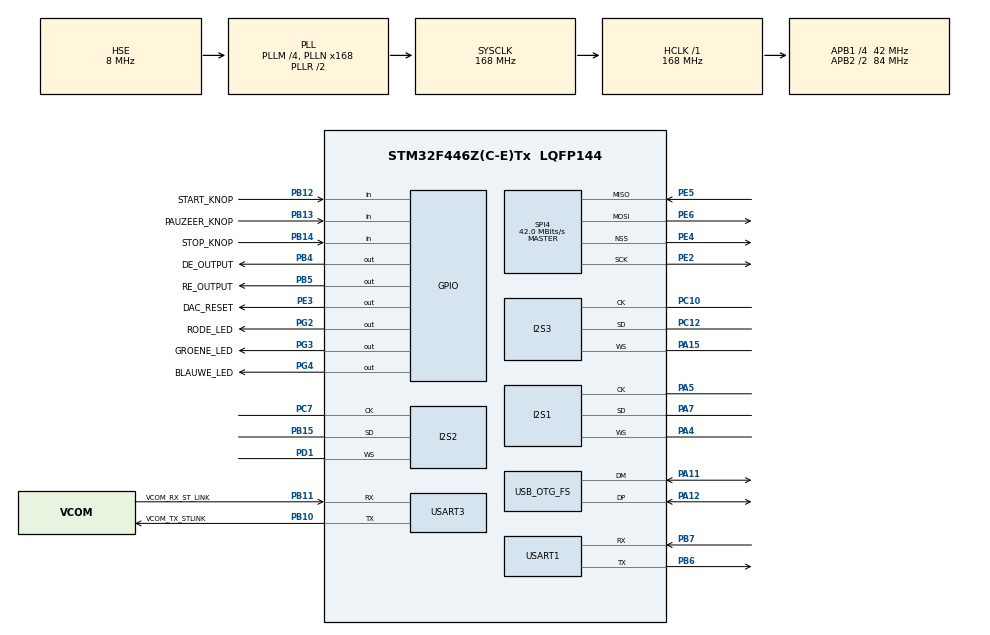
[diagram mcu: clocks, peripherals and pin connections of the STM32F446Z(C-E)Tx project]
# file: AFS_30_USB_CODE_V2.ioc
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I2S1.AudioFreq=I2S_AUDIOFREQ_48K
I2S1.DataFormat=I2S_DATAFORMAT_24B
I2S1.ErrorAudioFreq=1.72 %
I2S1.FullDuplexMode=I2S_FULLDUPLEXMODE_DISABLE
I2S1.Instance=SPI$Index
I2S1.RealAudioFreq=48.828 KHz
I2S1.Standard=I2S_STANDARD_PHILIPS
I2S1.VirtualMode=I2S_MODE_MASTER
I2S2.AudioFreq=I2S_AUDIOFREQ_48K
I2S2.DataFormat=I2S_DATAFORMAT_24B
I2S2.ErrorAudioFreq=1.72 %
I2S2.FullDuplexMode=I2S_FULLDUPLEXMODE_DISABLE
I2S2.Instance=SPI$Index
I2S2.RealAudioFreq=48.828 KHz
I2S2.VirtualMode=I2S_MODE_MASTER
I2S3.AudioFreq=I2S_AUDIOFREQ_48K
I2S3.DataFormat=I2S_DATAFORMAT_24B
I2S3.ErrorAudioFreq=1.72 %
I2S3.FullDuplexMode=I2S_FULLDUPLEXMODE_DISABLE
I2S3.Instance=SPI$Index
I2S3.RealAudioFreq=48.828 KHz
I2S3.VirtualMode=I2S_MODE_MASTER
Mcu.Family=STM32F4
Mcu.Name=STM32F446Z(C-E)Tx
Mcu.Package=LQFP144
NVIC.OTG_FS_IRQn=true\:0\:0\:false\:false\:true\:false\:true\:true
NVIC.PriorityGroup=NVIC_PRIORITYGROUP_4
PA11.Mode=Device_Only
PA11.Signal=USB_OTG_FS_DM
PA12.Mode=Device_Only
PA12.Signal=USB_OTG_FS_DP
PA13.Mode=Serial_Wire
PA13.Signal=SYS_JTMS-SWDIO
PA14.Mode=Serial_Wire
PA14.Signal=SYS_JTCK-SWCLK
PA15.Mode=Half_Duplex_Master
PA15.Signal=I2S3_WS
PA4.Mode=Half_Duplex_Master
PA4.Signal=I2S1_WS
PA5.Mode=Half_Duplex_Master
PA5.Signal=I2S1_CK
PA7.Mode=Half_Duplex_Master
PA7.Signal=I2S1_SD
PB10.GPIO_Label=VCOM_TX_STLINK
PB10.Mode=Asynchronous
PB10.Signal=USART3_TX
PB11.GPIO_Label=VCOM_RX_ST_LINK
PB11.Mode=Asynchronous
PB11.Signal=USART3_RX
PB12.GPIO_Label=START_KNOP
PB12.Signal=GPIO_Input
PB13.GPIO_Label=PAUZEER_KNOP
PB13.Signal=GPIO_Input
PB14.GPIO_Label=STOP_KNOP
PB14.Signal=GPIO_Input
PB15.Mode=Half_Duplex_Master
PB15.Signal=I2S2_SD
PB4.GPIO_Label=DE_OUTPUT
PB4.Signal=GPIO_Output
PB5.GPIO_Label=RE_OUTPUT
PB5.Signal=GPIO_Output
PB6.Mode=Asynchronous
PB6.Signal=USART1_TX
PB7.Mode=Asynchronous
PB7.Signal=USART1_RX
PC10.Mode=Half_Duplex_Master
PC10.Signal=I2S3_CK
PC12.Mode=Half_Duplex_Master
PC12.Signal=I2S3_SD
PC7.Mode=Half_Duplex_Master
PC7.Signal=I2S2_CK
PD1.Mode=Half_Duplex_Master
PD1.Signal=I2S2_WS
PE2.Mode=Full_Duplex_Master
PE2.Signal=SPI4_SCK
PE3.GPIO_Label=DAC_RESET
PE3.Signal=GPIO_Output
PE4.Mode=NSS_Signal_Hard_Output
PE4.Signal=SPI4_NSS
PE5.Mode=Full_Duplex_Master
PE5.Signal=SPI4_MISO
PE6.Mode=Full_Duplex_Master
PE6.Signal=SPI4_MOSI
PG2.GPIO_Label=RODE_LED
PG2.Signal=GPIO_Output
PG3.GPIO_Label=GROENE_LED
PG3.Signal=GPIO_Output
PG4.GPIO_Label=BLAUWE_LED
PG4.Signal=GPIO_Output
PH0-OSC_IN.Mode=HSE-External-Oscillator
PH0-OSC_IN.Signal=RCC_OSC_IN
PH1-OSC_OUT.Mode=HSE-External-Oscillator
PH1-OSC_OUT.Signal=RCC_OSC_OUT
ProjectManager.HeapSize=0x200
ProjectManager.StackSize=0x400
ProjectManager.TargetToolchain=STM32CubeIDE
RCC.AHBFreq_Value=168000000
RCC.APB1CLKDivider=RCC_HCLK_DIV4
RCC.APB1Freq_Value=42000000
RCC.APB1TimFreq_Value=84000000
RCC.APB2CLKDivider=RCC_HCLK_DIV2
RCC.APB2Freq_Value=84000000
RCC.APB2TimFreq_Value=168000000
RCC.CortexFreq_Value=168000000
RCC.HCLKFreq_Value=168000000
RCC.HSE_VALUE=8000000
RCC.PLLI2SM=6
RCC.PLLI2SN=75
RCC.PLLM=4
RCC.PLLN=168
RCC.PLLQ=7
RCC.SYSCLKFreq_VALUE=168000000
RCC.SYSCLKSource=RCC_SYSCLKSOURCE_PLLRCLK
RCC.USBFreq_Value=48000000
RCC.VCOOutputFreq_Value=336000000
SPI4.BaudRatePrescaler=SPI_BAUDRATEPRESCALER_2
SPI4.CalculateBaudRate=42.0 MBits/s
SPI4.Direction=SPI_DIRECTION_2LINES
SPI4.Mode=SPI_MODE_MASTER
SPI4.VirtualNSS=VM_NSSHARD
SPI4.VirtualType=VM_MASTER
USART1.VirtualMode=VM_ASYNC
USART3.VirtualMode=VM_ASYNC
USB_DEVICE.CLASS_NAME_FS=CDC
USB_DEVICE.PRODUCT_STRING_CDC_FS=YOUNES STM32
USB_DEVICE.VirtualMode-CDC_FS=Cdc
USB_DEVICE.VirtualModeFS=Cdc_FS
USB_OTG_FS.VirtualMode=Device_Only
VP_USB_DEVICE_VS_USB_DEVICE_CDC_FS.Mode=CDC_FS
board=custom

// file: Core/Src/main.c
/* USER CODE BEGIN Header */
/**
  ******************************************************************************
  * @file           : main.c
  * @brief          : Main program body
  ******************************************************************************
  * @attention
  *
  * Copyright (c) 2024 STMicroelectronics.
  * All rights reserved.
  *
  * This software is licensed under terms that can be found in the LICENSE file
  * in the root directory of this software component.
  * If no LICENSE file comes with this software, it is provided AS-IS.
  *
  ******************************************************************************
  */
/* USER CODE END Header */
#include "main.h"
#include "usb_device.h"

I2S_HandleTypeDef hi2s1;
I2S_HandleTypeDef hi2s2;
I2S_HandleTypeDef hi2s3;

SPI_HandleTypeDef hspi4;

UART_HandleTypeDef huart1;
UART_HandleTypeDef huart3;

/* USER CODE BEGIN PV */

char *data= "Hello world, USB is working \r\n";
uint8_t buffer [64];
char receivedData[100];  // Buffer to store received data
uint32_t receivedLength = 0;
/* USER CODE END PV */

void SystemClock_Config(void);
void PeriphCommonClock_Config(void);
static void MX_GPIO_Init(void);
static void MX_I2S1_Init(void);
static void MX_I2S2_Init(void);
static void MX_I2S3_Init(void);
static void MX_SPI4_Init(void);
static void MX_USART1_UART_Init(void);
static void MX_USART3_UART_Init(void);

/* USER CODE BEGIN 0 */
void CheckReceivedData(void)
{
  /* Check if the received data contains the target string */
  if (strstr(receivedData, "Hello world, USB is working") != NULL) {

    /* Clear the buffer after matching */
    memset(receivedData, '\0', sizeof(receivedData));
    receivedLength = 0;
  }

}
/* USER CODE END 0 */

int main(void)
{

  /* MCU Configuration--------------------------------------------------------*/

  /* Reset of all peripherals, Initializes the Flash interface and the Systick. */
  HAL_Init();

  /* Configure the system clock */
  SystemClock_Config();

/* Configure the peripherals common clocks */
  PeriphCommonClock_Config();

  /* Initialize all configured peripherals */
  MX_GPIO_Init();
  MX_I2S1_Init();
  MX_I2S2_Init();
  MX_I2S3_Init();
  MX_SPI4_Init();
  MX_USART1_UART_Init();
  MX_USART3_UART_Init();
  MX_USB_DEVICE_Init();
  /* USER CODE BEGIN 2 */

  /////// KLOK FREQEUNTIE OP 12 MHZ zetten////
  /////// KLOK FREQEUNTIE OP 12 MHZ zetten////
  /////// KLOK FREQEUNTIE OP 12 MHZ zetten////
  /////// KLOK FREQEUNTIE OP 12 MHZ zetten////

  /////// KLOK FREQEUNTIE OP 8 MHZ zetten////
  /////// KLOK FREQEUNTIE OP 8 MHZ zetten voor nucleo board////

  for (int var = 0; var <12; ++var) {
 	    CDC_Transmit_FS((uint8_t *)data,strlen (data));
 	    HAL_Delay(1000);

 }

  /* USER CODE END 2 */

  /* Infinite loop */
  /* USER CODE BEGIN WHILE */
  while (1)
  {
	  CheckReceivedData();

    /* USER CODE END WHILE */

  }
}

void SystemClock_Config(void)
{
  RCC_OscInitTypeDef RCC_OscInitStruct = {0};
  RCC_ClkInitTypeDef RCC_ClkInitStruct = {0};

  /** Configure the main internal regulator output voltage
  */
  __HAL_RCC_PWR_CLK_ENABLE();
  __HAL_PWR_VOLTAGESCALING_CONFIG(PWR_REGULATOR_VOLTAGE_SCALE1);

  /** Initializes the RCC Oscillators according to the specified parameters
  * in the RCC_OscInitTypeDef structure.
  */
  RCC_OscInitStruct.OscillatorType = RCC_OSCILLATORTYPE_HSE;
  RCC_OscInitStruct.HSEState = RCC_HSE_ON;
  RCC_OscInitStruct.PLL.PLLState = RCC_PLL_ON;
  RCC_OscInitStruct.PLL.PLLSource = RCC_PLLSOURCE_HSE;
  RCC_OscInitStruct.PLL.PLLM = 4;
  RCC_OscInitStruct.PLL.PLLN = 168;
  RCC_OscInitStruct.PLL.PLLP = RCC_PLLP_DIV2;
  RCC_OscInitStruct.PLL.PLLQ = 7;
  RCC_OscInitStruct.PLL.PLLR = 2;
  if (HAL_RCC_OscConfig(&RCC_OscInitStruct) != HAL_OK)
  {
    Error_Handler();
  }

  /** Initializes the CPU, AHB and APB buses clocks
  */
  RCC_ClkInitStruct.ClockType = RCC_CLOCKTYPE_HCLK|RCC_CLOCKTYPE_SYSCLK
                              |RCC_CLOCKTYPE_PCLK1|RCC_CLOCKTYPE_PCLK2;
  RCC_ClkInitStruct.SYSCLKSource = RCC_SYSCLKSOURCE_PLLRCLK;
  RCC_ClkInitStruct.AHBCLKDivider = RCC_SYSCLK_DIV1;
  RCC_ClkInitStruct.APB1CLKDivider = RCC_HCLK_DIV4;
  RCC_ClkInitStruct.APB2CLKDivider = RCC_HCLK_DIV2;

  if (HAL_RCC_ClockConfig(&RCC_ClkInitStruct, FLASH_LATENCY_5) != HAL_OK)
  {
    Error_Handler();
  }
}

void PeriphCommonClock_Config(void)
{
  RCC_PeriphCLKInitTypeDef PeriphClkInitStruct = {0};

  /** Initializes the peripherals clock
  */
  PeriphClkInitStruct.PeriphClockSelection = RCC_PERIPHCLK_I2S_APB1|RCC_PERIPHCLK_I2S_APB2;
  PeriphClkInitStruct.PLLI2S.PLLI2SN = 75;
  PeriphClkInitStruct.PLLI2S.PLLI2SP = RCC_PLLI2SP_DIV2;
  PeriphClkInitStruct.PLLI2S.PLLI2SM = 6;
  PeriphClkInitStruct.PLLI2S.PLLI2SR = 2;
  PeriphClkInitStruct.PLLI2S.PLLI2SQ = 2;
  PeriphClkInitStruct.PLLI2SDivQ = 1;
  PeriphClkInitStruct.I2sApb2ClockSelection = RCC_I2SAPB2CLKSOURCE_PLLI2S;
  PeriphClkInitStruct.I2sApb1ClockSelection = RCC_I2SAPB1CLKSOURCE_PLLI2S;
  if (HAL_RCCEx_PeriphCLKConfig(&PeriphClkInitStruct) != HAL_OK)
  {
    Error_Handler();
  }
}

static void MX_I2S1_Init(void)
{

  hi2s1.Instance = SPI1;
  hi2s1.Init.Mode = I2S_MODE_MASTER_TX;
  hi2s1.Init.Standard = I2S_STANDARD_PHILIPS;
  hi2s1.Init.DataFormat = I2S_DATAFORMAT_24B;
  hi2s1.Init.MCLKOutput = I2S_MCLKOUTPUT_DISABLE;
  hi2s1.Init.AudioFreq = I2S_AUDIOFREQ_48K;
  hi2s1.Init.CPOL = I2S_CPOL_LOW;
  hi2s1.Init.ClockSource = I2S_CLOCK_PLL;
  hi2s1.Init.FullDuplexMode = I2S_FULLDUPLEXMODE_DISABLE;
  if (HAL_I2S_Init(&hi2s1) != HAL_OK)
  {
    Error_Handler();
  }

}

static void MX_I2S2_Init(void)
{

  hi2s2.Instance = SPI2;
  hi2s2.Init.Mode = I2S_MODE_MASTER_TX;
  hi2s2.Init.Standard = I2S_STANDARD_PHILIPS;
  hi2s2.Init.DataFormat = I2S_DATAFORMAT_24B;
  hi2s2.Init.MCLKOutput = I2S_MCLKOUTPUT_DISABLE;
  hi2s2.Init.AudioFreq = I2S_AUDIOFREQ_48K;
  hi2s2.Init.CPOL = I2S_CPOL_LOW;
  hi2s2.Init.ClockSource = I2S_CLOCK_PLL;
  hi2s2.Init.FullDuplexMode = I2S_FULLDUPLEXMODE_DISABLE;
  if (HAL_I2S_Init(&hi2s2) != HAL_OK)
  {
    Error_Handler();
  }

}

static void MX_I2S3_Init(void)
{

  hi2s3.Instance = SPI3;
  hi2s3.Init.Mode = I2S_MODE_MASTER_TX;
  hi2s3.Init.Standard = I2S_STANDARD_PHILIPS;
  hi2s3.Init.DataFormat = I2S_DATAFORMAT_24B;
  hi2s3.Init.MCLKOutput = I2S_MCLKOUTPUT_DISABLE;
  hi2s3.Init.AudioFreq = I2S_AUDIOFREQ_48K;
  hi2s3.Init.CPOL = I2S_CPOL_LOW;
  hi2s3.Init.ClockSource = I2S_CLOCK_PLL;
  hi2s3.Init.FullDuplexMode = I2S_FULLDUPLEXMODE_DISABLE;
  if (HAL_I2S_Init(&hi2s3) != HAL_OK)
  {
    Error_Handler();
  }

}

static void MX_SPI4_Init(void)
{

  /* SPI4 parameter configuration*/
  hspi4.Instance = SPI4;
  hspi4.Init.Mode = SPI_MODE_MASTER;
  hspi4.Init.Direction = SPI_DIRECTION_2LINES;
  hspi4.Init.DataSize = SPI_DATASIZE_8BIT;
  hspi4.Init.CLKPolarity = SPI_POLARITY_LOW;
  hspi4.Init.CLKPhase = SPI_PHASE_1EDGE;
  hspi4.Init.NSS = SPI_NSS_HARD_OUTPUT;
  hspi4.Init.BaudRatePrescaler = SPI_BAUDRATEPRESCALER_2;
  hspi4.Init.FirstBit = SPI_FIRSTBIT_MSB;
  hspi4.Init.TIMode = SPI_TIMODE_DISABLE;
  hspi4.Init.CRCCalculation = SPI_CRCCALCULATION_DISABLE;
  hspi4.Init.CRCPolynomial = 10;
  if (HAL_SPI_Init(&hspi4) != HAL_OK)
  {
    Error_Handler();
  }

}

static void MX_USART1_UART_Init(void)
{

  huart1.Instance = USART1;
  huart1.Init.BaudRate = 115200;
  huart1.Init.WordLength = UART_WORDLENGTH_8B;
  huart1.Init.StopBits = UART_STOPBITS_1;
  huart1.Init.Parity = UART_PARITY_NONE;
  huart1.Init.Mode = UART_MODE_TX_RX;
  huart1.Init.HwFlowCtl = UART_HWCONTROL_NONE;
  huart1.Init.OverSampling = UART_OVERSAMPLING_16;
  if (HAL_UART_Init(&huart1) != HAL_OK)
  {
    Error_Handler();
  }

}

static void MX_USART3_UART_Init(void)
{

  huart3.Instance = USART3;
  huart3.Init.BaudRate = 115200;
  huart3.Init.WordLength = UART_WORDLENGTH_8B;
  huart3.Init.StopBits = UART_STOPBITS_1;
  huart3.Init.Parity = UART_PARITY_NONE;
  huart3.Init.Mode = UART_MODE_TX_RX;
  huart3.Init.HwFlowCtl = UART_HWCONTROL_NONE;
  huart3.Init.OverSampling = UART_OVERSAMPLING_16;
  if (HAL_UART_Init(&huart3) != HAL_OK)
  {
    Error_Handler();
  }

}

static void MX_GPIO_Init(void)
{
  GPIO_InitTypeDef GPIO_InitStruct = {0};

  /* GPIO Ports Clock Enable */
  __HAL_RCC_GPIOE_CLK_ENABLE();
  __HAL_RCC_GPIOH_CLK_ENABLE();
  __HAL_RCC_GPIOA_CLK_ENABLE();
  __HAL_RCC_GPIOB_CLK_ENABLE();
  __HAL_RCC_GPIOG_CLK_ENABLE();
  __HAL_RCC_GPIOC_CLK_ENABLE();
  __HAL_RCC_GPIOD_CLK_ENABLE();

  /*Configure GPIO pin Output Level */
  HAL_GPIO_WritePin(DAC_RESET_GPIO_Port, DAC_RESET_Pin, GPIO_PIN_RESET);

  /*Configure GPIO pin Output Level */
  HAL_GPIO_WritePin(GPIOG, RODE_LED_Pin|GROENE_LED_Pin|BLAUWE_LED_Pin, GPIO_PIN_RESET);

  /*Configure GPIO pin Output Level */
  HAL_GPIO_WritePin(GPIOB, DE_OUTPUT_Pin|RE_OUTPUT_Pin, GPIO_PIN_RESET);

  /*Configure GPIO pin : DAC_RESET_Pin */
  GPIO_InitStruct.Pin = DAC_RESET_Pin;
  GPIO_InitStruct.Mode = GPIO_MODE_OUTPUT_PP;
  GPIO_InitStruct.Pull = GPIO_NOPULL;
  GPIO_InitStruct.Speed = GPIO_SPEED_FREQ_LOW;
  HAL_GPIO_Init(DAC_RESET_GPIO_Port, &GPIO_InitStruct);

  /*Configure GPIO pins : START_KNOP_Pin PAUZEER_KNOP_Pin STOP_KNOP_Pin */
  GPIO_InitStruct.Pin = START_KNOP_Pin|PAUZEER_KNOP_Pin|STOP_KNOP_Pin;
  GPIO_InitStruct.Mode = GPIO_MODE_INPUT;
  GPIO_InitStruct.Pull = GPIO_NOPULL;
  HAL_GPIO_Init(GPIOB, &GPIO_InitStruct);

  /*Configure GPIO pins : RODE_LED_Pin GROENE_LED_Pin BLAUWE_LED_Pin */
  GPIO_InitStruct.Pin = RODE_LED_Pin|GROENE_LED_Pin|BLAUWE_LED_Pin;
  GPIO_InitStruct.Mode = GPIO_MODE_OUTPUT_PP;
  GPIO_InitStruct.Pull = GPIO_NOPULL;
  GPIO_InitStruct.Speed = GPIO_SPEED_FREQ_LOW;
  HAL_GPIO_Init(GPIOG, &GPIO_InitStruct);

  /*Configure GPIO pins : DE_OUTPUT_Pin RE_OUTPUT_Pin */
  GPIO_InitStruct.Pin = DE_OUTPUT_Pin|RE_OUTPUT_Pin;
  GPIO_InitStruct.Mode = GPIO_MODE_OUTPUT_PP;
  GPIO_InitStruct.Pull = GPIO_NOPULL;
  GPIO_InitStruct.Speed = GPIO_SPEED_FREQ_LOW;
  HAL_GPIO_Init(GPIOB, &GPIO_InitStruct);

}

void Error_Handler(void)
{
  __disable_irq();
  while (1)
  {
  }
}
